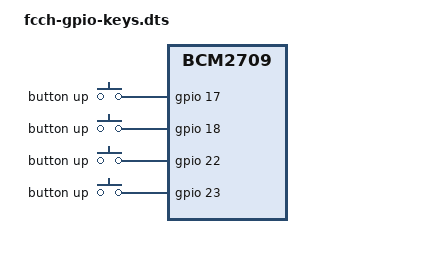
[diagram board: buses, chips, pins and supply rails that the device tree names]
/dts-v1/;
/plugin/;
 
/ {
    compatible = "brcm,bcm2835", "brcm,bcm2708", "brcm,bcm2709";
 
    fragment@0 {
        target = <&gpio>;
        __overlay__ {
            gpiokeys_pins: gpiokeys_pins {
                brcm,pins = <17 18 22 23>;
                brcm,function = <0>; /* input */
                brcm,pull = <1>;     /* pull-down */
            };
        };
    };
 
    fragment@1 {
    target-path = "/soc";
        __overlay__ {
            gpiokeys: gpiokeys {
                compatible = "gpio-keys";
                #address-cells = <1>;
                #size-cells = <0>;
                pinctrl-names = "default";
                pinctrl-0 = <&gpiokeys_pins>;
                status = "okay";
 
                button@17 {
                    label = "button up";
                    linux,code = <103>;
                    gpios = <&gpio 17 0>;
                };
 
                button@18 {
                    label = "button up";
                    linux,code = <108>;
                    gpios = <&gpio 18 0>;
                };
 
                button@22 {
                    label = "button up";
                    linux,code = <105>;
                    gpios = <&gpio 22 0>;
                };
 
                button@23 {
                    label = "button up";
                    linux,code = <106>;
                    gpios = <&gpio 23 0>;
                };
            };
        };
    };
};
